# ioam3358 register map
Registers are 32-bit, access not given, no defined reset value unless marked. A register's access mark holds for its fields unless they carry their own. Addresses are absolute; registers are grouped by the start of their names; [hi:lo] are bit positions; {n}, {i} and the like mark numbered series; 'fields as' and 'values as' point back to an identical list.

## CONTROL
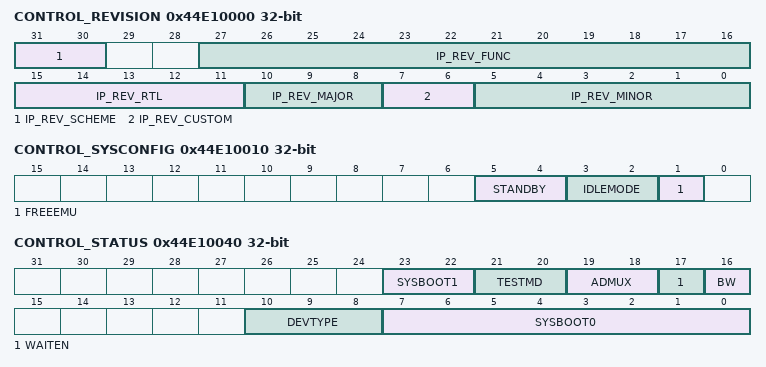
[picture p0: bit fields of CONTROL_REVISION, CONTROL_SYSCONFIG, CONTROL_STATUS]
0x44E10000 CONTROL_REVISION
  [31:30] IP_REV_SCHEME, [27:16] IP_REV_FUNC, [15:11] IP_REV_RTL, [10:8] IP_REV_MAJOR, [7:6] IP_REV_CUSTOM, [5:0] IP_REV_MINOR
0x44E10004 CONTROL_HWINFO
0x44E10010 CONTROL_SYSCONFIG
  [5:4] STANDBY, [3:2] IDLEMODE, [1] FREEEMU
0x44E10040 CONTROL_STATUS
  [23:22] SYSBOOT1, [21:20] TESTMD, [19:18] ADMUX, [17] WAITEN, [16] BW, [10:8] DEVTYPE, [7:0] SYSBOOT0

## BANDGAP
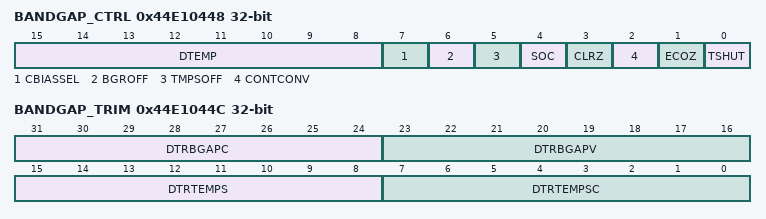
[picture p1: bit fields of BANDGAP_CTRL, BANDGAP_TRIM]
0x44E10448 BANDGAP_CTRL
  [15:8] DTEMP, [7] CBIASSEL, [6] BGROFF, [5] TMPSOFF, [4] SOC, [3] CLRZ, [2] CONTCONV, [1] ECOZ, [0] TSHUT
0x44E1044C BANDGAP_TRIM
  [31:24] DTRBGAPC, [23:16] DTRBGAPV, [15:8] DTRTEMPS, [7:0] DTRTEMPSC

## INIT
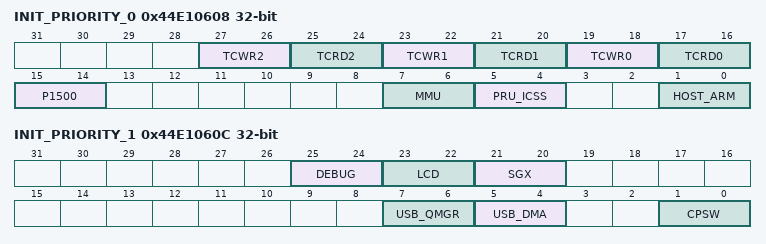
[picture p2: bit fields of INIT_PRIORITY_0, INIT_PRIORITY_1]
0x44E10608 INIT_PRIORITY_0
  [27:26] TCWR2, [25:24] TCRD2, [23:22] TCWR1, [21:20] TCRD1, [19:18] TCWR0, [17:16] TCRD0, [15:14] P1500, [7:6] MMU, [5:4] PRU_ICSS, [1:0] HOST_ARM
0x44E1060C INIT_PRIORITY_1
  [25:24] DEBUG, [23:22] LCD, [21:20] SGX, [7:6] USB_QMGR, [5:4] USB_DMA, [1:0] CPSW

## USB
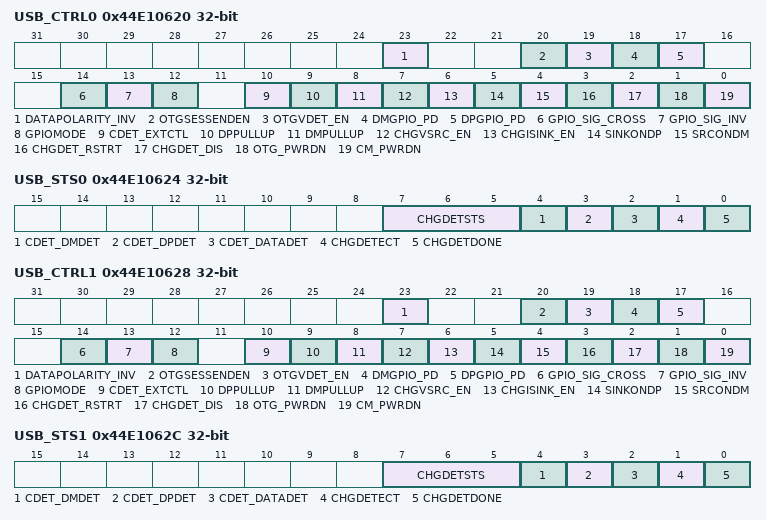
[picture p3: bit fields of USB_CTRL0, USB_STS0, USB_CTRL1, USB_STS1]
0x44E10620 USB_CTRL0
  [23] DATAPOLARITY_INV, [20] OTGSESSENDEN, [19] OTGVDET_EN, [18] DMGPIO_PD, [17] DPGPIO_PD, [14] GPIO_SIG_CROSS, [13] GPIO_SIG_INV, [12] GPIOMODE, [10] CDET_EXTCTL, [9] DPPULLUP, [8] DMPULLUP, [7] CHGVSRC_EN, [6] CHGISINK_EN, [5] SINKONDP, [4] SRCONDM, [3] CHGDET_RSTRT, [2] CHGDET_DIS, [1] OTG_PWRDN, [0] CM_PWRDN
0x44E10624 USB_STS0
  [7:5] CHGDETSTS, [4] CDET_DMDET, [3] CDET_DPDET, [2] CDET_DATADET, [1] CHGDETECT, [0] CHGDETDONE
0x44E10628 USB_CTRL1
  fields as USB_CTRL0
0x44E1062C USB_STS1
  fields as USB_STS0
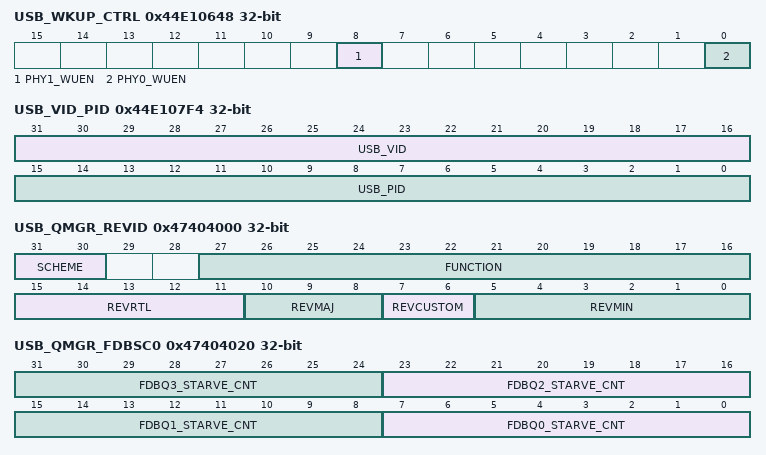
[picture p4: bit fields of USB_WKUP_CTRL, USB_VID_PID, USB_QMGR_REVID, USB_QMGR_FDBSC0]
0x44E10648 USB_WKUP_CTRL
  [8] PHY1_WUEN, [0] PHY0_WUEN
0x44E107F4 USB_VID_PID
  [31:16] USB_VID, [15:0] USB_PID
0x47404000 USB_QMGR_REVID
  [31:30] SCHEME, [27:16] FUNCTION, [15:11] REVRTL, [10:8] REVMAJ, [7:6] REVCUSTOM, [5:0] REVMIN
0x47404008 USB_QMGR_RST
0x47404020 USB_QMGR_FDBSC0
  [8n+7:8n] FDBQ{n}_STARVE_CNT (n=0..3)
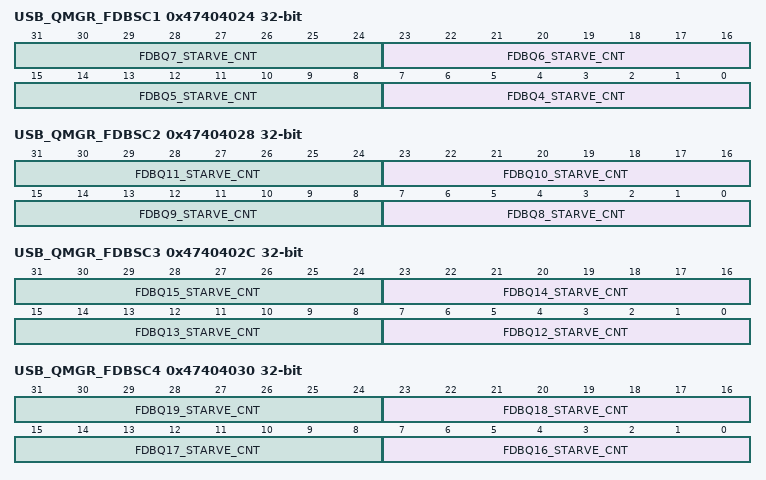
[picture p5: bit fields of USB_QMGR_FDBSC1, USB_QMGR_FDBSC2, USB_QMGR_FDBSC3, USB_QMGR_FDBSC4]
0x47404024 USB_QMGR_FDBSC1
  [8n-25:8n-32] FDBQ{n}_STARVE_CNT (n=4..7)
0x47404028 USB_QMGR_FDBSC2
  [8n-57:8n-64] FDBQ{n}_STARVE_CNT (n=8..11)
0x4740402C USB_QMGR_FDBSC3
  [8n-89:8n-96] FDBQ{n}_STARVE_CNT (n=12..15)
0x47404030 USB_QMGR_FDBSC4
  [8n-121:8n-128] FDBQ{n}_STARVE_CNT (n=16..19)
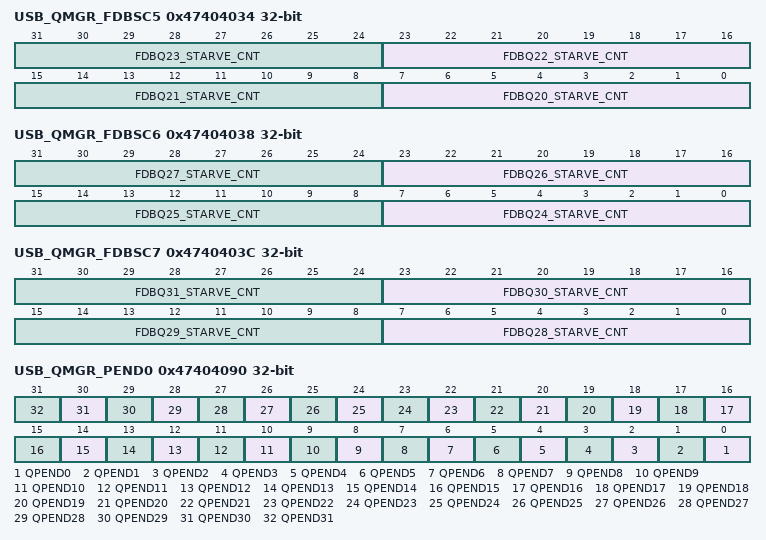
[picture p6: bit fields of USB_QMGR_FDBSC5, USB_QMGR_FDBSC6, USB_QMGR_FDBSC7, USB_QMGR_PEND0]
0x47404034 USB_QMGR_FDBSC5
  [8n-153:8n-160] FDBQ{n}_STARVE_CNT (n=20..23)
0x47404038 USB_QMGR_FDBSC6
  [8n-185:8n-192] FDBQ{n}_STARVE_CNT (n=24..27)
0x4740403C USB_QMGR_FDBSC7
  [8n-217:8n-224] FDBQ{n}_STARVE_CNT (n=28..31)
0x47404080 USB_QMGR_LRAM0BASE
0x47404084 USB_QMGR_LRAM0SIZE
  [13:0] REGION0_SIZE
0x47404088 USB_QMGR_LRAM1BASE
0x47404090 USB_QMGR_PEND0
  [n] QPEND{n} (n=0..31)
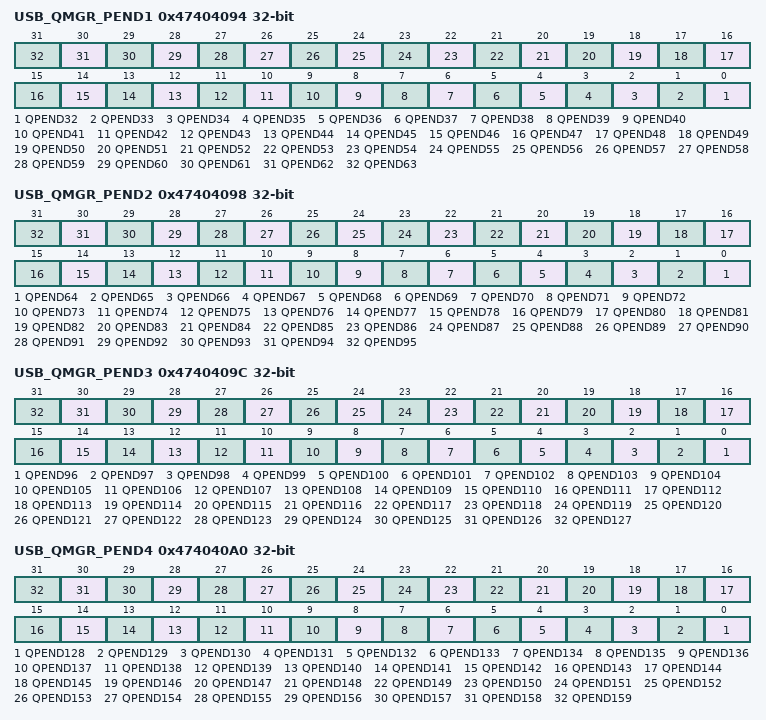
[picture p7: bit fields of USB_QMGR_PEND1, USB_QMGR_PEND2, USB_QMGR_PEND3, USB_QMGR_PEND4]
0x47404094 USB_QMGR_PEND1
  [n-32] QPEND{n} (n=32..63)
0x47404098 USB_QMGR_PEND2
  [n-64] QPEND{n} (n=64..95)
0x4740409C USB_QMGR_PEND3
  [n-96] QPEND{n} (n=96..127)
0x474040A0 USB_QMGR_PEND4
  [n-128] QPEND{n} (n=128..159)
{0x47405000+0x10*i} USB_QMGR_QMEMRBASE{i} (i=0..7)
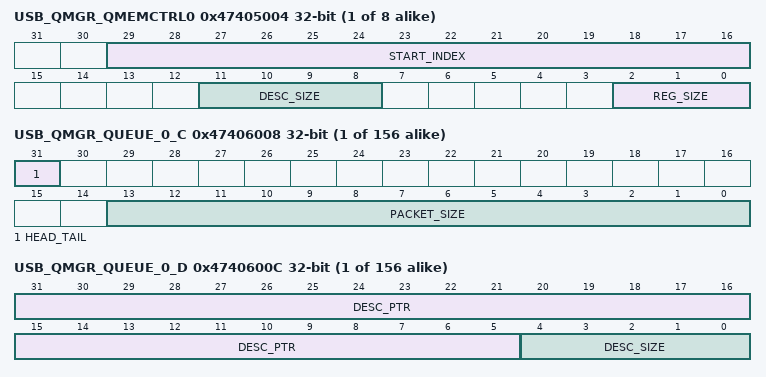
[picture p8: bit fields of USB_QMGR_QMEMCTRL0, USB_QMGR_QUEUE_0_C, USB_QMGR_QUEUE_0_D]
{0x47405004+0x10*i} USB_QMGR_QMEMCTRL{i} (i=0..7)
  [29:16] START_INDEX, [11:8] DESC_SIZE, [2:0] REG_SIZE
{0x47406000+0x10*i} USB_QMGR_QUEUE_{i}_A (i=0..155)
  [13:0] QUEUE_ENTRY_COUNT
{0x47406004+0x10*i} USB_QMGR_QUEUE_{i}_B (i=0..155)
  [27:0] QUEUE_BYTE_COUNT
{0x47406008+0x10*i} USB_QMGR_QUEUE_{i}_C (i=0..155)
  [31] HEAD_TAIL, [13:0] PACKET_SIZE
{0x4740600C+0x10*i} USB_QMGR_QUEUE_{i}_D (i=0..155)
  [31:5] DESC_PTR, [4:0] DESC_SIZE
{0x47407000+0x10*i} USB_QMGR_QUEUE_{i}_STATUS_A (i=0..155)
  [13:0] QUEUE_ENTRY_COUNT
{0x47407004+0x10*i} USB_QMGR_QUEUE_{i}_STATUS_B (i=0..155)
  [27:0] QUEUE_BYTE_COUNT
{0x47407008+0x10*i} USB_QMGR_QUEUE_{i}_STATUS_C (i=0..155)
  [13:0] PACKET_SIZE

## MAC
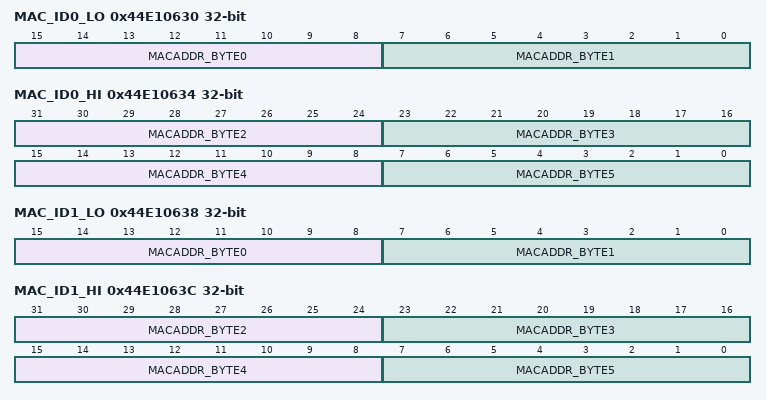
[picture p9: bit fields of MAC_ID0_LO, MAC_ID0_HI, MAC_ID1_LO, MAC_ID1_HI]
0x44E10630 MAC_ID0_LO
  [15:8] MACADDR_BYTE0, [7:0] MACADDR_BYTE1
0x44E10634 MAC_ID0_HI
  [47-8n:40-8n] MACADDR_BYTE{n} (n=2..5)
0x44E10638 MAC_ID1_LO
  [15:8] MACADDR_BYTE0, [7:0] MACADDR_BYTE1
0x44E1063C MAC_ID1_HI
  [47-8n:40-8n] MACADDR_BYTE{n} (n=2..5)
